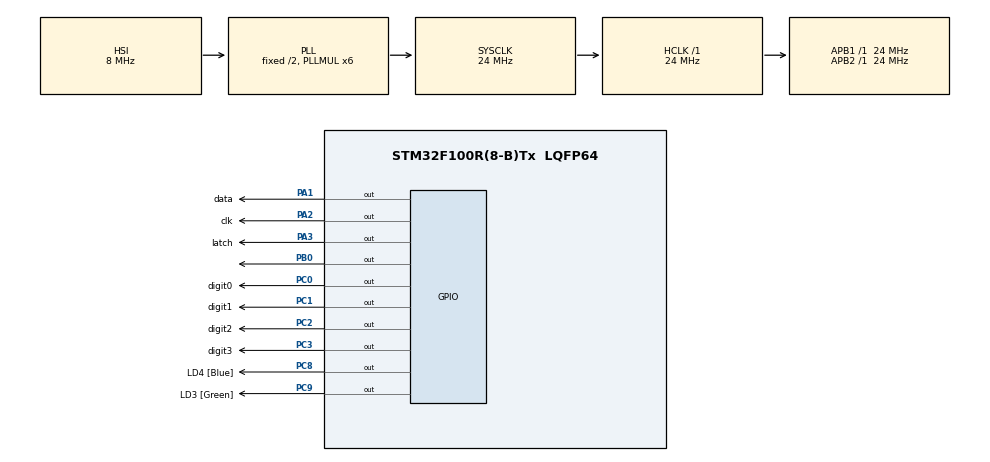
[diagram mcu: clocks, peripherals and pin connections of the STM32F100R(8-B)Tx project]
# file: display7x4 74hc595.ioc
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Mcu.Family=STM32F1
Mcu.Name=STM32F100R(8-B)Tx
Mcu.Package=LQFP64
NVIC.PriorityGroup=NVIC_PRIORITYGROUP_4
NVIC.TIM1_TRG_COM_TIM17_IRQn=true\:0\:0\:false\:false\:true\:true\:true
NVIC.TIM2_IRQn=true\:0\:0\:false\:false\:true\:true\:true
PA0-WKUP.Mode=SYS_WakeUp0
PA0-WKUP.Signal=SYS_WKUP
PA1.GPIO_Label=data
PA1.Signal=GPIO_Output
PA13.GPIO_Label=TMS_SWDIO
PA13.Mode=Serial_Wire
PA13.Signal=SYS_JTMS-SWDIO
PA14.GPIO_Label=TCK_SWCLK
PA14.Mode=Serial_Wire
PA14.Signal=SYS_JTCK-SWCLK
PA2.GPIO_Label=clk
PA2.Signal=GPIO_Output
PA3.GPIO_Label=latch
PA3.Signal=GPIO_Output
PB0.Signal=GPIO_Output
PC0.GPIO_Label=digit0
PC0.Signal=GPIO_Output
PC1.GPIO_Label=digit1
PC1.Signal=GPIO_Output
PC14-OSC32_IN.Mode=LSE-External-Oscillator
PC14-OSC32_IN.Signal=RCC_OSC32_IN
PC15-OSC32_OUT.Mode=LSE-External-Oscillator
PC15-OSC32_OUT.Signal=RCC_OSC32_OUT
PC2.GPIO_Label=digit2
PC2.Signal=GPIO_Output
PC3.GPIO_Label=digit3
PC3.Signal=GPIO_Output
PC8.GPIO_Label=LD4 [Blue]
PC8.Signal=GPIO_Output
PC9.GPIO_Label=LD3 [Green]
PC9.Signal=GPIO_Output
PD0-OSC_IN.Mode=HSE-External-Oscillator
PD0-OSC_IN.Signal=RCC_OSC_IN
PD1-OSC_OUT.Mode=HSE-External-Oscillator
PD1-OSC_OUT.Signal=RCC_OSC_OUT
ProjectManager.HeapSize=0x200
ProjectManager.StackSize=0x400
ProjectManager.TargetToolchain=STM32CubeIDE
RCC.AHBFreq_Value=24000000
RCC.APB1Freq_Value=24000000
RCC.APB1TimFreq_Value=24000000
RCC.APB2Freq_Value=24000000
RCC.APB2TimFreq_Value=24000000
RCC.HCLKFreq_Value=24000000
RCC.PLLMUL=RCC_PLL_MUL6
RCC.SYSCLKFreq_VALUE=24000000
RCC.SYSCLKSource=RCC_SYSCLKSOURCE_PLLCLK
TIM1.Prescaler=23999
TIM17.Period=1
TIM17.Prescaler=23999
VP_TIM17_VS_ClockSourceINT.Mode=Enable_Timer
VP_TIM1_VS_ClockSourceINT.Mode=Internal
VP_TIM2_VS_ClockSourceINT.Mode=Internal
board=STM32VLDISCOVERY

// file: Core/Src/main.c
/* USER CODE BEGIN Header */
/**
  ******************************************************************************
  * @file           : main.c
  * @brief          : Main program body
  ******************************************************************************
  * @attention
  *
  * <h2><center>&copy; Copyright (c) 2020 STMicroelectronics.
  * All rights reserved.</center></h2>
  *
  * This software component is licensed by ST under BSD 3-Clause license,
  * the "License"; You may not use this file except in compliance with the
  * License. You may obtain a copy of the License at:
  *                        opensource.org/licenses/BSD-3-Clause
  *
  ******************************************************************************
  */
/* USER CODE END Header */

#include "main.h"

TIM_HandleTypeDef htim1;
TIM_HandleTypeDef htim2;
TIM_HandleTypeDef htim17;

/* USER CODE BEGIN PV */
struct led_display disp1;
/* USER CODE END PV */

void SystemClock_Config(void);
static void MX_GPIO_Init(void);
static void MX_TIM1_Init(void);
static void MX_TIM17_Init(void);
static void MX_TIM2_Init(void);
/* USER CODE BEGIN PFP */
void HAL_TIM_PeriodElapsedCallback(TIM_HandleTypeDef *htim)
{
	HAL_GPIO_WritePin(GPIOC, GPIO_PIN_8, GPIO_PIN_SET);

	if(htim->Instance == TIM17){
		display_number(&disp1);
			}

}

/* USER CODE END PFP */

int main(void)
{

  /* MCU Configuration--------------------------------------------------------*/

  /* Reset of all peripherals, Initializes the Flash interface and the Systick. */
  HAL_Init();

  /* Configure the system clock */
  SystemClock_Config();

  /* Initialize all configured peripherals */
  MX_GPIO_Init();
  MX_TIM1_Init();
  MX_TIM17_Init();
  MX_TIM2_Init();
  /* USER CODE BEGIN 2 */

  disp1 = setup_led_display();
  change_number(&disp1, 0);
  HAL_TIM_Base_Start_IT(&htim17);
  int i =0;
  /* USER CODE END 2 */

  /* Infinite loop */
  while (1)
  {

    /* USER CODE BEGIN 3 */
	  HAL_Delay(100);
	  change_number(&disp1, i++);

  }
  /* USER CODE END 3 */
}

void SystemClock_Config(void)
{
  RCC_OscInitTypeDef RCC_OscInitStruct = {0};
  RCC_ClkInitTypeDef RCC_ClkInitStruct = {0};

  /** Initializes the CPU, AHB and APB busses clocks
  */
  RCC_OscInitStruct.OscillatorType = RCC_OSCILLATORTYPE_HSI;
  RCC_OscInitStruct.HSIState = RCC_HSI_ON;
  RCC_OscInitStruct.HSICalibrationValue = RCC_HSICALIBRATION_DEFAULT;
  RCC_OscInitStruct.PLL.PLLState = RCC_PLL_ON;
  RCC_OscInitStruct.PLL.PLLSource = RCC_PLLSOURCE_HSI_DIV2;
  RCC_OscInitStruct.PLL.PLLMUL = RCC_PLL_MUL6;
  if (HAL_RCC_OscConfig(&RCC_OscInitStruct) != HAL_OK)
  {
    Error_Handler();
  }
  /** Initializes the CPU, AHB and APB busses clocks
  */
  RCC_ClkInitStruct.ClockType = RCC_CLOCKTYPE_HCLK|RCC_CLOCKTYPE_SYSCLK
                              |RCC_CLOCKTYPE_PCLK1|RCC_CLOCKTYPE_PCLK2;
  RCC_ClkInitStruct.SYSCLKSource = RCC_SYSCLKSOURCE_PLLCLK;
  RCC_ClkInitStruct.AHBCLKDivider = RCC_SYSCLK_DIV1;
  RCC_ClkInitStruct.APB1CLKDivider = RCC_HCLK_DIV1;
  RCC_ClkInitStruct.APB2CLKDivider = RCC_HCLK_DIV1;

  if (HAL_RCC_ClockConfig(&RCC_ClkInitStruct, FLASH_LATENCY_0) != HAL_OK)
  {
    Error_Handler();
  }
}

static void MX_TIM1_Init(void)
{

  TIM_ClockConfigTypeDef sClockSourceConfig = {0};
  TIM_MasterConfigTypeDef sMasterConfig = {0};

  htim1.Instance = TIM1;
  htim1.Init.Prescaler = 23999;
  htim1.Init.CounterMode = TIM_COUNTERMODE_UP;
  htim1.Init.Period = 0;
  htim1.Init.ClockDivision = TIM_CLOCKDIVISION_DIV1;
  htim1.Init.RepetitionCounter = 0;
  htim1.Init.AutoReloadPreload = TIM_AUTORELOAD_PRELOAD_DISABLE;
  if (HAL_TIM_Base_Init(&htim1) != HAL_OK)
  {
    Error_Handler();
  }
  sClockSourceConfig.ClockSource = TIM_CLOCKSOURCE_INTERNAL;
  if (HAL_TIM_ConfigClockSource(&htim1, &sClockSourceConfig) != HAL_OK)
  {
    Error_Handler();
  }
  sMasterConfig.MasterOutputTrigger = TIM_TRGO_RESET;
  sMasterConfig.MasterSlaveMode = TIM_MASTERSLAVEMODE_DISABLE;
  if (HAL_TIMEx_MasterConfigSynchronization(&htim1, &sMasterConfig) != HAL_OK)
  {
    Error_Handler();
  }

}

static void MX_TIM2_Init(void)
{

  TIM_ClockConfigTypeDef sClockSourceConfig = {0};
  TIM_MasterConfigTypeDef sMasterConfig = {0};

  htim2.Instance = TIM2;
  htim2.Init.Prescaler = 0;
  htim2.Init.CounterMode = TIM_COUNTERMODE_UP;
  htim2.Init.Period = 0;
  htim2.Init.ClockDivision = TIM_CLOCKDIVISION_DIV1;
  htim2.Init.AutoReloadPreload = TIM_AUTORELOAD_PRELOAD_DISABLE;
  if (HAL_TIM_Base_Init(&htim2) != HAL_OK)
  {
    Error_Handler();
  }
  sClockSourceConfig.ClockSource = TIM_CLOCKSOURCE_INTERNAL;
  if (HAL_TIM_ConfigClockSource(&htim2, &sClockSourceConfig) != HAL_OK)
  {
    Error_Handler();
  }
  sMasterConfig.MasterOutputTrigger = TIM_TRGO_RESET;
  sMasterConfig.MasterSlaveMode = TIM_MASTERSLAVEMODE_DISABLE;
  if (HAL_TIMEx_MasterConfigSynchronization(&htim2, &sMasterConfig) != HAL_OK)
  {
    Error_Handler();
  }

}

static void MX_TIM17_Init(void)
{

  htim17.Instance = TIM17;
  htim17.Init.Prescaler = 23999;
  htim17.Init.CounterMode = TIM_COUNTERMODE_UP;
  htim17.Init.Period = 1;
  htim17.Init.ClockDivision = TIM_CLOCKDIVISION_DIV1;
  htim17.Init.RepetitionCounter = 0;
  htim17.Init.AutoReloadPreload = TIM_AUTORELOAD_PRELOAD_DISABLE;
  if (HAL_TIM_Base_Init(&htim17) != HAL_OK)
  {
    Error_Handler();
  }

}

static void MX_GPIO_Init(void)
{
  GPIO_InitTypeDef GPIO_InitStruct = {0};

  /* GPIO Ports Clock Enable */
  __HAL_RCC_GPIOC_CLK_ENABLE();
  __HAL_RCC_GPIOD_CLK_ENABLE();
  __HAL_RCC_GPIOA_CLK_ENABLE();
  __HAL_RCC_GPIOB_CLK_ENABLE();

  /*Configure GPIO pin Output Level */
  HAL_GPIO_WritePin(GPIOC, digit0_Pin|digit1_Pin|digit2_Pin|digit3_Pin
                          |LD4_Pin|LD3_Pin, GPIO_PIN_RESET);

  /*Configure GPIO pin Output Level */
  HAL_GPIO_WritePin(GPIOA, data_Pin|clk_Pin|latch_Pin, GPIO_PIN_RESET);

  /*Configure GPIO pin Output Level */
  HAL_GPIO_WritePin(GPIOB, GPIO_PIN_0, GPIO_PIN_RESET);

  /*Configure GPIO pins : digit0_Pin digit1_Pin digit2_Pin digit3_Pin
                           LD4_Pin LD3_Pin */
  GPIO_InitStruct.Pin = digit0_Pin|digit1_Pin|digit2_Pin|digit3_Pin
                          |LD4_Pin|LD3_Pin;
  GPIO_InitStruct.Mode = GPIO_MODE_OUTPUT_PP;
  GPIO_InitStruct.Pull = GPIO_NOPULL;
  GPIO_InitStruct.Speed = GPIO_SPEED_FREQ_LOW;
  HAL_GPIO_Init(GPIOC, &GPIO_InitStruct);

  /*Configure GPIO pins : data_Pin clk_Pin latch_Pin */
  GPIO_InitStruct.Pin = data_Pin|clk_Pin|latch_Pin;
  GPIO_InitStruct.Mode = GPIO_MODE_OUTPUT_PP;
  GPIO_InitStruct.Pull = GPIO_NOPULL;
  GPIO_InitStruct.Speed = GPIO_SPEED_FREQ_LOW;
  HAL_GPIO_Init(GPIOA, &GPIO_InitStruct);

  /*Configure GPIO pin : PB0 */
  GPIO_InitStruct.Pin = GPIO_PIN_0;
  GPIO_InitStruct.Mode = GPIO_MODE_OUTPUT_PP;
  GPIO_InitStruct.Pull = GPIO_NOPULL;
  GPIO_InitStruct.Speed = GPIO_SPEED_FREQ_LOW;
  HAL_GPIO_Init(GPIOB, &GPIO_InitStruct);

}

void Error_Handler(void)
{
}

/************************ (C) COPYRIGHT STMicroelectronics *****END OF FILE****/
